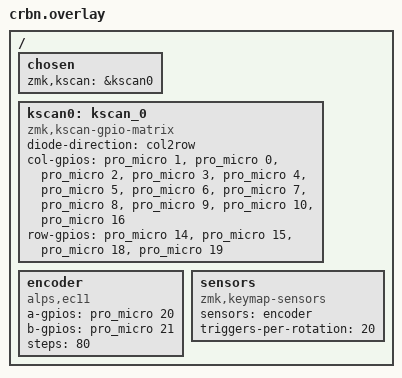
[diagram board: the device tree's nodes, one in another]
/*
 * Copyright (c) 2020 The ZMK Contributors
 *
 * SPDX-License-Identifier: MIT
 */

#include <dt-bindings/zmk/matrix_transform.h>

/ {
    chosen {
        zmk,kscan = &kscan0;
    };

    kscan0: kscan_0 {
        compatible = "zmk,kscan-gpio-matrix";
        diode-direction = "col2row";

        col-gpios
            = <&pro_micro 1 GPIO_ACTIVE_HIGH>
            , <&pro_micro 0 GPIO_ACTIVE_HIGH>
            , <&pro_micro 2 GPIO_ACTIVE_HIGH>
            , <&pro_micro 3 GPIO_ACTIVE_HIGH>
            , <&pro_micro 4 GPIO_ACTIVE_HIGH>
            , <&pro_micro 5 GPIO_ACTIVE_HIGH>
            , <&pro_micro 6 GPIO_ACTIVE_HIGH>
            , <&pro_micro 7 GPIO_ACTIVE_HIGH>
            , <&pro_micro 8 GPIO_ACTIVE_HIGH>
            , <&pro_micro 9 GPIO_ACTIVE_HIGH>
            , <&pro_micro 10 GPIO_ACTIVE_HIGH>
            , <&pro_micro 16 GPIO_ACTIVE_HIGH>
            ;

        row-gpios
            = <&pro_micro 14 (GPIO_ACTIVE_HIGH | GPIO_PULL_DOWN)>
            , <&pro_micro 15 (GPIO_ACTIVE_HIGH | GPIO_PULL_DOWN)>
            , <&pro_micro 18 (GPIO_ACTIVE_HIGH | GPIO_PULL_DOWN)>
            , <&pro_micro 19 (GPIO_ACTIVE_HIGH | GPIO_PULL_DOWN)>
            ;
    };

    encoder: encoder {
        compatible = "alps,ec11";
        a-gpios = <&pro_micro 20 (GPIO_ACTIVE_HIGH | GPIO_PULL_UP)>;
        b-gpios = <&pro_micro 21 (GPIO_ACTIVE_HIGH | GPIO_PULL_UP)>;
        steps = <80>;
        status = "okay";
    };

    sensors: sensors {
        compatible = "zmk,keymap-sensors";
        sensors = <&encoder>;
        triggers-per-rotation = <20>;
    };
};
